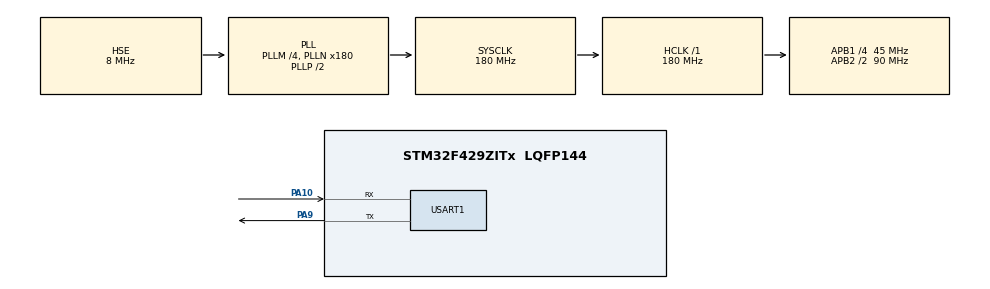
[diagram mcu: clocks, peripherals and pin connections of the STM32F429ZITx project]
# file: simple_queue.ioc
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FREERTOS.Tasks01=defaultTask,0,128,StartDefaultTask,Default,NULL,Dynamic,NULL,NULL
Mcu.Family=STM32F4
Mcu.Name=STM32F429ZITx
Mcu.Package=LQFP144
NVIC.PriorityGroup=NVIC_PRIORITYGROUP_4
NVIC.TIM1_UP_TIM10_IRQn=true\:15\:0\:false\:false\:true\:false\:false\:true\:true
NVIC.TimeBase=TIM1_UP_TIM10_IRQn
NVIC.TimeBaseIP=TIM1
NVIC.USART1_IRQn=true\:5\:0\:false\:false\:true\:true\:true\:true\:true
PA10.Mode=Asynchronous
PA10.Signal=USART1_RX
PA13.Mode=Serial_Wire
PA13.Signal=SYS_JTMS-SWDIO
PA14.Mode=Serial_Wire
PA14.Signal=SYS_JTCK-SWCLK
PA9.Mode=Asynchronous
PA9.Signal=USART1_TX
PH0/OSC_IN.Mode=HSE-External-Oscillator
PH0/OSC_IN.Signal=RCC_OSC_IN
PH1/OSC_OUT.Mode=HSE-External-Oscillator
PH1/OSC_OUT.Signal=RCC_OSC_OUT
ProjectManager.HeapSize=0x200
ProjectManager.StackSize=0x400
ProjectManager.TargetToolchain=STM32CubeIDE
RCC.48MHZClocksFreq_Value=120000000
RCC.AHBFreq_Value=180000000
RCC.APB1CLKDivider=RCC_HCLK_DIV4
RCC.APB1Freq_Value=45000000
RCC.APB1TimFreq_Value=90000000
RCC.APB2CLKDivider=RCC_HCLK_DIV2
RCC.APB2Freq_Value=90000000
RCC.APB2TimFreq_Value=180000000
RCC.CortexFreq_Value=180000000
RCC.HCLKFreq_Value=180000000
RCC.HSE_VALUE=8000000
RCC.HSI_VALUE=16000000
RCC.LSE_VALUE=32768
RCC.PLLM=4
RCC.PLLN=180
RCC.PLLQ=3
RCC.PLLSAIN=50
RCC.PLLSourceVirtual=RCC_PLLSOURCE_HSE
RCC.SYSCLKFreq_VALUE=180000000
RCC.SYSCLKSource=RCC_SYSCLKSOURCE_PLLCLK
RCC.VCOOutputFreq_Value=360000000
USART1.VirtualMode=VM_ASYNC
VP_FREERTOS_VS_CMSIS_V1.Mode=CMSIS_V1
VP_SYS_VS_tim1.Mode=TIM1
board=STM32F429I-DISC1

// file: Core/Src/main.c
/* USER CODE BEGIN Header */
/**
  ******************************************************************************
  * @file           : main.c
  * @brief          : Main program body
  ******************************************************************************
  * @attention
  *
  * Copyright (c) 2025 STMicroelectronics.
  * All rights reserved.
  *
  * This software is licensed under terms that can be found in the LICENSE file
  * in the root directory of this software component.
  * If no LICENSE file comes with this software, it is provided AS-IS.
  *
  ******************************************************************************
  */
/* USER CODE END Header */
#include "main.h"

/* USER CODE BEGIN Includes */

#include "FreeRTOS.h"
#include "task.h"
#include "timers.h"
#include "queue.h"
#include "semphr.h"
#include "event_groups.h"

#include "string.h"
#include "stdio.h"
/* USER CODE END Includes */

UART_HandleTypeDef huart1;

void SystemClock_Config(void);
static void MX_GPIO_Init(void);
static void MX_USART1_UART_Init(void);

/* USER CODE BEGIN 0 */

/*********************************Task Handles*********************************************/

TaskHandle_t Sender_HPT_Handler;
TaskHandle_t Sender_LPT_Handler;
TaskHandle_t Receiver_Handler;

/*********************************QUEUE Handles*********************************************/
QueueHandle_t SimpleQueue;

/*********************************Task Functions*********************************************/
void Sender_HPT_Task (void *argumrent);
void Sender_LPT_Task (void *argumrent);
void Receiver_Task (void *argumrent);

uint8_t Rx_data;
/* USER CODE END 0 */

int main(void)
{

  /* MCU Configuration--------------------------------------------------------*/

  /* Reset of all peripherals, Initializes the Flash interface and the Systick. */
  HAL_Init();

  /* Configure the system clock */
  SystemClock_Config();

  /* Initialize all configured peripherals */
  MX_GPIO_Init();
  MX_USART1_UART_Init();
  /* USER CODE BEGIN 2 */

  /*********************************Create Integer Queue********************************************/
  SimpleQueue = xQueueCreate(5, sizeof (int));
  if (SimpleQueue == 0)  //queeue not created
  {
	  char *str = "Unable to create Integer Queue\n\n";
	  HAL_UART_Transmit(&huart1, (uint8_t *) str, strlen(str), HAL_MAX_DELAY);
  }
  else
  {
	  char *str = "Integer Queue created successfully\n\n";
	  HAL_UART_Transmit(&huart1, (uint8_t *) str, strlen(str), HAL_MAX_DELAY);
  }

  /*********************************Task Related********************************************/

  xTaskCreate(Sender_HPT_Task, "HPT_SEND", 128, NULL, 3, &Sender_HPT_Handler);
  xTaskCreate(Sender_LPT_Task, "LPT_SEND", 128, (void *)111, 2, &Sender_LPT_Handler);

  xTaskCreate(Receiver_Task, "Receive", 128, NULL, 1, &Receiver_Handler);

  HAL_UART_Receive_IT(&huart1, &Rx_data, 1);

  vTaskStartScheduler();

  /* USER CODE END 2 */

  /* Infinite loop */
  while (1)
  {

  }
}

void SystemClock_Config(void)
{
  RCC_OscInitTypeDef RCC_OscInitStruct = {0};
  RCC_ClkInitTypeDef RCC_ClkInitStruct = {0};

  /** Configure the main internal regulator output voltage
  */
  __HAL_RCC_PWR_CLK_ENABLE();
  __HAL_PWR_VOLTAGESCALING_CONFIG(PWR_REGULATOR_VOLTAGE_SCALE1);

  /** Initializes the RCC Oscillators according to the specified parameters
  * in the RCC_OscInitTypeDef structure.
  */
  RCC_OscInitStruct.OscillatorType = RCC_OSCILLATORTYPE_HSE;
  RCC_OscInitStruct.HSEState = RCC_HSE_ON;
  RCC_OscInitStruct.PLL.PLLState = RCC_PLL_ON;
  RCC_OscInitStruct.PLL.PLLSource = RCC_PLLSOURCE_HSE;
  RCC_OscInitStruct.PLL.PLLM = 4;
  RCC_OscInitStruct.PLL.PLLN = 180;
  RCC_OscInitStruct.PLL.PLLP = RCC_PLLP_DIV2;
  RCC_OscInitStruct.PLL.PLLQ = 3;
  if (HAL_RCC_OscConfig(&RCC_OscInitStruct) != HAL_OK)
  {
    Error_Handler();
  }

  /** Activate the Over-Drive mode
  */
  if (HAL_PWREx_EnableOverDrive() != HAL_OK)
  {
    Error_Handler();
  }

  /** Initializes the CPU, AHB and APB buses clocks
  */
  RCC_ClkInitStruct.ClockType = RCC_CLOCKTYPE_HCLK|RCC_CLOCKTYPE_SYSCLK
                              |RCC_CLOCKTYPE_PCLK1|RCC_CLOCKTYPE_PCLK2;
  RCC_ClkInitStruct.SYSCLKSource = RCC_SYSCLKSOURCE_PLLCLK;
  RCC_ClkInitStruct.AHBCLKDivider = RCC_SYSCLK_DIV1;
  RCC_ClkInitStruct.APB1CLKDivider = RCC_HCLK_DIV4;
  RCC_ClkInitStruct.APB2CLKDivider = RCC_HCLK_DIV2;

  if (HAL_RCC_ClockConfig(&RCC_ClkInitStruct, FLASH_LATENCY_5) != HAL_OK)
  {
    Error_Handler();
  }
}

static void MX_USART1_UART_Init(void)
{

  huart1.Instance = USART1;
  huart1.Init.BaudRate = 115200;
  huart1.Init.WordLength = UART_WORDLENGTH_8B;
  huart1.Init.StopBits = UART_STOPBITS_1;
  huart1.Init.Parity = UART_PARITY_NONE;
  huart1.Init.Mode = UART_MODE_TX_RX;
  huart1.Init.HwFlowCtl = UART_HWCONTROL_NONE;
  huart1.Init.OverSampling = UART_OVERSAMPLING_16;
  if (HAL_UART_Init(&huart1) != HAL_OK)
  {
    Error_Handler();
  }

}

static void MX_GPIO_Init(void)
{

  /* GPIO Ports Clock Enable */
  __HAL_RCC_GPIOH_CLK_ENABLE();
  __HAL_RCC_GPIOA_CLK_ENABLE();

}

/* USER CODE BEGIN 4 */

void Sender_HPT_Task (void *argument)
{
	int i=222;
	uint32_t TickDelay = pdMS_TO_TICKS(2000); //Tick değerini mse çevrilmesi için fonk. configTICK_RATE_HZ ticki ayarlar.
												//configTICK_RATE_HZ değerinden bağımsız ms cinsinden değer hesaplar.
	while (1)
	{
		if (xQueueSend(SimpleQueue, &i, portMAX_DELAY) == pdPASS)
		{
			char *str2 = " Successfully sent the number to the queue\nLeaving SENDER_HPT Task\n\n\n";
			HAL_UART_Transmit(&huart1, (uint8_t *)str2, strlen (str2), HAL_MAX_DELAY);
		}
		vTaskDelay(TickDelay);
	}
}

void Sender_LPT_Task (void *argument)
{
	int ToSend;
	uint32_t TickDelay = pdMS_TO_TICKS(1000);
	ToSend = (int)(intptr_t) argument; // güvenli dönüşüm

	while (1)
	{
		char *str2 = " Entered SENDER_LPT task\n About to send a number to the queue";
		HAL_UART_Transmit(&huart1, (uint8_t *)str2, strlen (str2), HAL_MAX_DELAY);

		if(xQueueSend(SimpleQueue, &ToSend, portMAX_DELAY) == pdPASS)
		{
			char *str2 = " Successfully sent the number to the queue\nLeaving SENDER_LPT Task\n\n\n";
			HAL_UART_Transmit(&huart1, (uint8_t *)str2, strlen (str2), HAL_MAX_DELAY);
		}
		vTaskDelay(TickDelay);
	}
}

void Receiver_Task (void *argument)
{
	int received=0;
	char str[80];
	uint32_t TickDelay = pdMS_TO_TICKS(500);
	while (1)
	{
		if (xQueueReceive(SimpleQueue, &received, portMAX_DELAY) != pdTRUE)
		{
			HAL_UART_Transmit(&huart1, (uint8_t *)"Error in Receiving from Queue\n\n", 31, 1000);
		}
		else
		{
			sprintf(str, " Successfully RECEIVED the number %d to the queue\nLeaving RECEIVER Task\n\n\n",received);
			HAL_UART_Transmit(&huart1, (uint8_t *)str, strlen (str), HAL_MAX_DELAY);
		}
		vTaskDelay(TickDelay);
	}
}

void HAL_UART_RxCpltCallback(UART_HandleTypeDef *huart)
{
	HAL_UART_Receive_IT(huart, &Rx_data, 1);
	int ToSend = 123456789;
	if (Rx_data == 'r')
	{
		 /* The xHigherPriorityTaskWoken parameter must be initialized to pdFALSE as
		 it will get set to pdTRUE inside the interrupt safe API function if a
		 context switch is required. */
		BaseType_t xHigherPriorityTaskWoken = pdFALSE;

		if (xQueueSendToFrontFromISR(SimpleQueue, &ToSend, &xHigherPriorityTaskWoken) == pdPASS)
		{
			HAL_UART_Transmit(huart, (uint8_t *)"\n\nSent from ISR\n\n", 17, 500);
		}
		else
		{
		    HAL_UART_Transmit(huart, (uint8_t *)"QUEUE NULL!\n", 12, 100);
		}

		/* Pass the xHigherPriorityTaskWoken value into portEND_SWITCHING_ISR(). If
		 xHigherPriorityTaskWoken was set to pdTRUE inside xSemaphoreGiveFromISR()
		 then calling portEND_SWITCHING_ISR() will request a context switch. If
		 xHigherPriorityTaskWoken is still pdFALSE then calling
		 portEND_SWITCHING_ISR() will have no effect */

		portYIELD_FROM_ISR(xHigherPriorityTaskWoken);
	}
}
/* USER CODE END 4 */

void HAL_TIM_PeriodElapsedCallback(TIM_HandleTypeDef *htim)
{
  if (htim->Instance == TIM1) {
    HAL_IncTick();
  }
}

void Error_Handler(void)
{
  __disable_irq();
  while (1)
  {
  }
}
